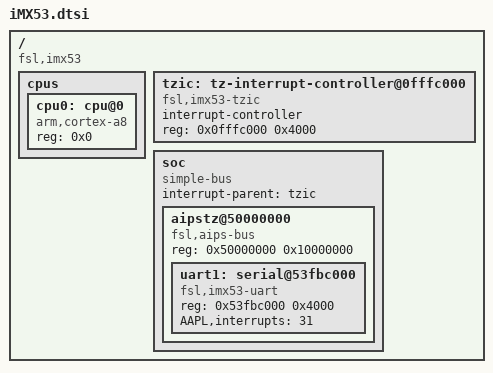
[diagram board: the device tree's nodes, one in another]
/*
 * i.MX53 Device Tree.
 *
 * Based on the Linux one.
 */

/ {
	compatible = "fsl,imx53", "AppleARM";
	
    /*
     * CPU nodes
     */
    cpus {
		#address-cells = <1>;
		#size-cells = <0>;
		cpu0: cpu@0 {
			device_type = "cpu";
			compatible = "arm,cortex-a8";
			reg = <0x0>;
		};
	};
	
	tzic: tz-interrupt-controller@0fffc000 {
		compatible = "fsl,imx53-tzic", "fsl,tzic";
		interrupt-controller;
		#interrupt-cells = <1>;
		reg = <0x0fffc000 0x4000>;
	};
	
	soc {
		#address-cells = <1>;
		#size-cells = <1>;
		compatible = "simple-bus";
		interrupt-parent = <&tzic>;
		ranges;

		aipstz@50000000 { /* AIPSTZ-1 */
			compatible = "fsl,aips-bus", "simple-bus";
			#address-cells = <1>;
			#size-cells = <1>;
			reg = <0x50000000 0x10000000>;
			ranges;

			uart1: serial@53fbc000 {
				compatible = "fsl,imx53-uart", "fsl,imx21-uart";
				reg = <0x53fbc000 0x4000>;
				AAPL,interrupts = <31>;
			};
		};
	};
};
